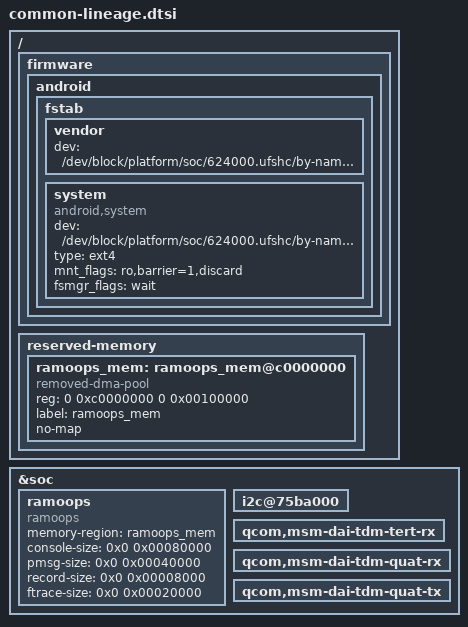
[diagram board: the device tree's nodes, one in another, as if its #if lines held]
/* Copyright (c) 2018 The LineageOS Project. All rights reserved.
 *
 * This program is free software; you can redistribute it and/or modify
 * it under the terms of the GNU General Public License version 2 and
 * only version 2 as published by the Free Software Foundation.
 *
 * This program is distributed in the hope that it will be useful,
 * but WITHOUT ANY WARRANTY; without even the implied warranty of
 * MERCHANTABILITY or FITNESS FOR A PARTICULAR PURPOSE.  See the
 * GNU General Public License for more details.
 */

/ {
	firmware: firmware {
		android {
			/delete-node/ vbmeta;
			fstab {
#ifdef CONFIG_LGE_MSM8996_ENABLE_VENDOR
				vendor {
                                        dev = "/dev/block/platform/soc/624000.ufshc/by-name/vendor";
                                };
#else
				/delete-node/ vendor;
#endif
				system {
					compatible = "android,system";
					dev = "/dev/block/platform/soc/624000.ufshc/by-name/system";
					type = "ext4";
					mnt_flags = "ro,barrier=1,discard";
					fsmgr_flags = "wait";
					status = "ok";
				};
			};
		};
	};
};

/ {
	reserved-memory {
		ramoops_mem: ramoops_mem@c0000000 {
			compatible = "removed-dma-pool";
			reg = <0 0xc0000000 0 0x00100000>;
			label = "ramoops_mem";
			no-map;
		};
	};
};

&soc {
	ramoops {
		compatible = "ramoops";
		memory-region = <&ramoops_mem>;
		console-size = <0x0 0x00080000>;
		pmsg-size    = <0x0 0x00040000>;
		record-size  = <0x0 0x00008000>;
		ftrace-size  = <0x0 0x00020000>;
		status = "ok";
	};

	i2c@75ba000 {
		/delete-node/ synaptics@20;
	};

	/delete-node/ gen-vkeys;

	qcom,msm-dai-tdm-tert-rx {
		/delete-property/ pinctrl-names;
		/delete-property/ pinctrl-0;
		/delete-property/ pinctrl-1;
	};

	qcom,msm-dai-tdm-quat-rx {
		/delete-property/ pinctrl-names;
		/delete-property/ pinctrl-0;
		/delete-property/ pinctrl-1;
	};

	qcom,msm-dai-tdm-quat-tx {
		/delete-property/ pinctrl-names;
		/delete-property/ pinctrl-0;
		/delete-property/ pinctrl-1;
	};
};
